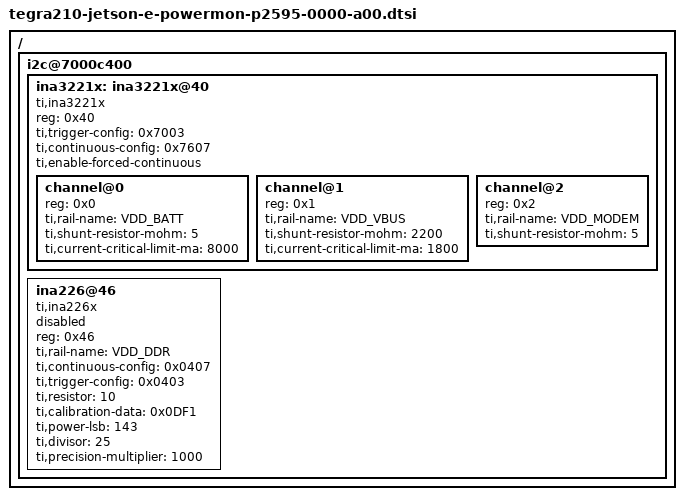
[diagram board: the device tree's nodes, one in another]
/*
 * Copyright (c) 2015, NVIDIA CORPORATION.  All rights reserved.
 *
 * This program is free software; you can redistribute it and/or modify
 * it under the terms of the GNU General Public License as published by
 * the Free Software Foundation; either version 2 of the License, or
 * (at your option) any later version.
 *
 * This program is distributed in the hope that it will be useful, but WITHOUT
 * ANY WARRANTY; without even the implied warranty of MERCHANTABILITY or
 * FITNESS FOR A PARTICULAR PURPOSE.  See the GNU General Public License for
 * more details.
 *
 * You should have received a copy of the GNU General Public License along
 * with this program; if not, write to the Free Software Foundation, Inc.,
 * 51 Franklin Street, Fifth Floor, Boston, MA  02110-1301, USA.
 */
/ {
	i2c@7000c400 {
		ina3221x: ina3221x@40 {
			compatible = "ti,ina3221x";
			reg = <0x40>;
			ti,trigger-config = <0x7003>;
			ti,continuous-config = <0x7607>;
			ti,enable-forced-continuous;
			#address-cells = <1>;
			#size-cells = <0>;
			#io-channel-cells = <1>;
			channel@0 {
				reg = <0x0>;
				ti,rail-name = "VDD_BATT";
				ti,shunt-resistor-mohm = <5>;
				ti,current-critical-limit-ma = <8000>;
			};

			channel@1 {
				reg = <0x1>;
				ti,rail-name = "VDD_VBUS";
				ti,shunt-resistor-mohm = <2200>;
				ti,current-critical-limit-ma = <1800>;
			};

			channel@2 {
				reg = <0x2>;
				ti,rail-name = "VDD_MODEM";
				ti,shunt-resistor-mohm = <5>;
			};
		};

		ina226@46 {
			status = "disabled";
			compatible = "ti,ina226x";
			reg = <0x46>;
			ti,rail-name = "VDD_DDR";
			ti,continuous-config = <0x0407>;
			ti,trigger-config = <0x0403>;
			ti,resistor = <10>;
			ti,calibration-data = <0x0DF1>;
			ti,power-lsb = <143>;
			ti,divisor = <25>;
			ti,precision-multiplier = <1000>;
		};
	};
};
